# cslr_sgmii register map
Vendor: Texas Instruments
Peripheral module from a debugger description file (folder TCI6484_C6457).
Registers are 32-bit, access not given, reset 0x0 unless marked. A register's access mark holds for its fields unless they carry their own. Offsets are as the file gives them; lines under a group give offsets from that group; [hi:lo] are bit positions; {n}, {i} and the like mark numbered series; 'fields as' and 'values as' point back to an identical list; <NAME> marks a mode.

## SGMII — Serial Gigabit Media independent Interface
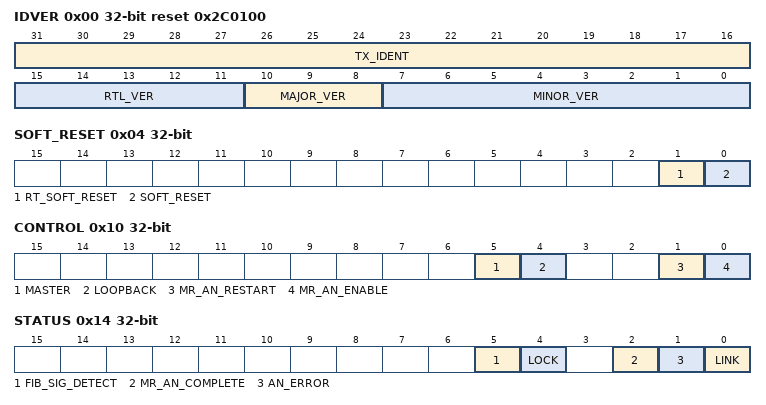
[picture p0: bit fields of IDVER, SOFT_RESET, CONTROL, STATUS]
0x00 IDVER ro reset 0x2C0100 — Identification and Version register
  [31:16] TX_IDENT — TX identification value
  [15:11] RTL_VER — RTL version value
  [10:8] MAJOR_VER — Major version value
  [7:0] MINOR_VER — Minor version value
0x04 SOFT_RESET — Software Reset Register
  [1] RT_SOFT_RESET rw — Transmit and Receive Software Reset. Writing 1 to this bit causes the CPSGMII Transmit and Receive logic to be in reset condition
  [0] SOFT_RESET rw — Software reset  Writing a one to this bit causes the CPSGMII logic to be reset. Software reset occurs immediately
0x10 CONTROL
  [5] MASTER rw — Master mode
  [4] LOOPBACK rw — Loop back mode. In loop back mode the transmit clock(TX_CLK) is used for transmit/receive and auto-negotiation is bypassed
  [1] MR_AN_RESTART rw — Auto-Negotiation restart
  [0] MR_AN_ENABLE rw — Auto-Negotiation enable
0x14 STATUS
  [5] FIB_SIG_DETECT ro — Fiber Signal Detect  This is the FIB_SIG_DETECT input pin
  [4] LOCK ro — Lock  This is the Lock input pin
  [2] MR_AN_COMPLETE ro — Auto-negotiation complete. This value is not valid until the lock status bit is asserted
  [1] AN_ERROR ro — Auto-negotiation error. For SGMII mode an auto-negotiation error occurs when half duplex gigabit is commanded. For FIBER mode, auto-negotiation error occurs when both sides can not be full duplex This bit is not valid until the lock status bit is asserted
  [0] LINK ro — Link. This value is not valid until the lock status bit is asserted
0x18 MR_ADV_ABILITY — Advertised Ability Register
  [15:0] MR_ADV_ABILITY rw — Advertised Ability
0x20 MR_LP_ADV_ABILITY — Link Partner Advertised Ability Register
  [15:0] MR_LP_ADV_ABILITY ro — Link Partner Advertised Ability
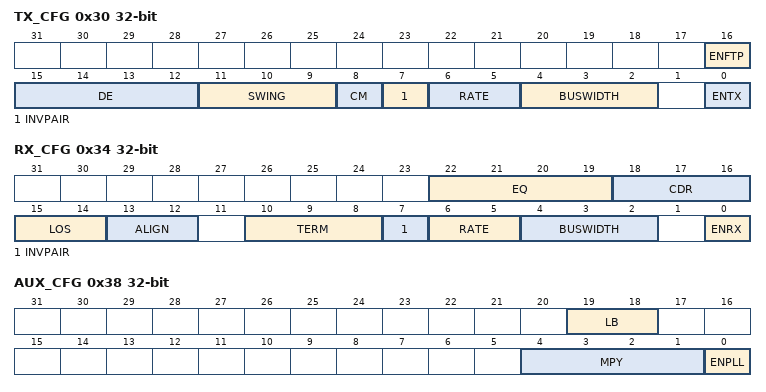
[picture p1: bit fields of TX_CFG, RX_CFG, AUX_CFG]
0x30 TX_CFG — Transmit Configuration Register
  [16] ENFTP rw — Enables fixed-phase relationship of transmit input clock with respect to transmit output clock.
  [15:12] DE rw — De-emphasis.
  [11:9] SWING rw — Output swing.
  [8] CM rw — Common mode.
    0=NORMAL; 1=RAISED
  [7] INVPAIR rw — Invert polarity.
    0=NORMAL; 1=INVERTED
  [6:5] RATE rw — Operating rate.
  [4:2] BUSWIDTH rw
  [0] ENTX rw — Enable Transmitter
    0=DISABLE; 1=ENABLE
0x34 RX_CFG — Receive Configuration Register
  [22:19] EQ rw — Equalizer.
  [18:16] CDR rw — Clock/data recovery.
  [15:14] LOS rw — Loss of signal.
  [13:12] ALIGN rw — Symbol alignment.
  [10:8] TERM rw — Input termination.
  [7] INVPAIR rw — Invert polarity.
    0=NORMAL; 1=INVERTED
  [6:5] RATE rw — Operating rate.
  [4:2] BUSWIDTH rw
  [0] ENRX rw — Enable receiver
    0=DISABLE; 1=ENABLE
0x38 AUX_CFG — Auxiliary Configuration Register
  [19:18] LB rw — Loop bandwidth.
  [4:1] MPY rw — PLL multiply.
  [0] ENPLL rw — Enable PLL.
    0=DISABLE; 1=ENABLE
